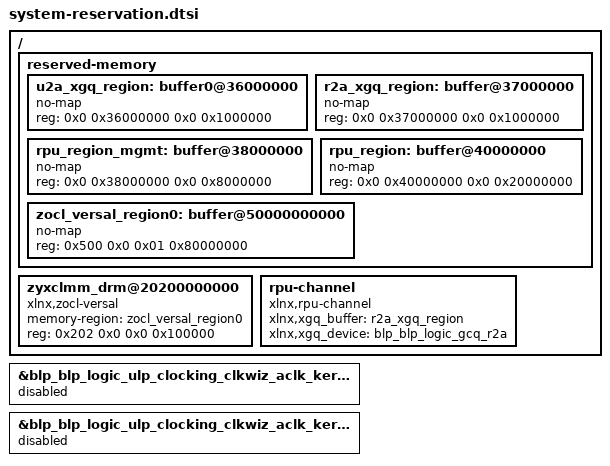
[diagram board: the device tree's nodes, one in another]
/ {
	reserved-memory {
        	#address-cells = <0x2>;
        	#size-cells = <0x2>;
        	ranges;

        	u2a_xgq_region: buffer0@36000000 {
            		no-map;
            		reg = <0x0 0x36000000 0x0 0x1000000>;
        	};

        	r2a_xgq_region: buffer@37000000 {
            		no-map;
            		reg = <0x0 0x37000000 0x0 0x1000000>;
        	};

		rpu_region_mgmt: buffer@38000000 {
                        no-map;
                        reg = <0x0 0x38000000 0x0 0x8000000>;
                };

		rpu_region: buffer@40000000 {
			no-map;
			reg = <0x0 0x40000000 0x0 0x20000000>;
		};

        	zocl_versal_region0: buffer@50000000000 {
            		no-map;
            		reg = <0x500 0x0 0x01 0x80000000>;
        	};

    	};
	zyxclmm_drm@20200000000 {
                compatible = "xlnx,zocl-versal";
                status = "okay";
                memory-region = <&zocl_versal_region0>;
                reg = <0x202 0x0 0x0 0x100000>;
        };
	rpu-channel {
                compatible = "xlnx,rpu-channel";
                xlnx,xgq_buffer = <&r2a_xgq_region>;
                xlnx,xgq_device = <&blp_blp_logic_gcq_r2a>;
                interrupt-names = "irq_sq";
        };
};

&blp_blp_logic_ulp_clocking_clkwiz_aclk_kernel_01 {
	status = "disabled";
};

&blp_blp_logic_ulp_clocking_clkwiz_aclk_kernel_00 {
	status = "disabled";
};

